# CY8C5868AXI_LP035 register map
File version: 0.1
Registers are 8-bit, read-write, no defined reset value unless marked. A register's access mark holds for its fields unless they carry their own. Offsets are from the block's base; [hi:lo] are bit positions; {n}, {i} and the like mark numbered series; 'fields as' and 'values as' point back to an identical list.

## LFSR
Base 0x40006406
0x00 SINGLE_CYCLE_SEED 14-bit — Current seed value
0x20 SINGLE_CYCLE_POLYNOMIAL 14-bit — Current polynomial value
0x40 SINGLE_CYCLE_COPY 14-bit — Copy seed value

## Length_Counter_1
Base 0x00000000
0x40006402 Length_Counter_1_COUNTER — UDB.A0 - Current Counter Value
0x40006422 Length_Counter_1_PERIOD — UDB.D0 - Assigned Period
0x40006432 Length_Counter_1_COMPARE — UDB.D1 - Assigned Compare Value
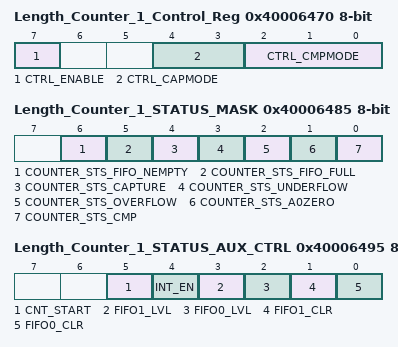
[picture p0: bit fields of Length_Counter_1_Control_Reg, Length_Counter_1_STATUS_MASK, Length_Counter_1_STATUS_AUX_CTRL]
0x40006470 Length_Counter_1_Control_Reg — UDB Control Register - Assigned Control Register Value
  [7] CTRL_ENABLE — Enable Counter
  [4:3] CTRL_CAPMODE — Capture mode
  [2:0] CTRL_CMPMODE — Compare mode
0x40006485 Length_Counter_1_STATUS_MASK — UDB Status bits Interrupt Mask Enable Register
  [6] COUNTER_STS_FIFO_NEMPTY — FIFO Not Empty Status
  [5] COUNTER_STS_FIFO_FULL — FIFO Full Status
  [4] COUNTER_STS_CAPTURE — Capture Status
  [3] COUNTER_STS_UNDERFLOW — Underflow status
  [2] COUNTER_STS_OVERFLOW — Overflow status
  [1] COUNTER_STS_A0ZERO — A0 Zero ouput status
  [0] COUNTER_STS_CMP — Compare output status
0x40006495 Length_Counter_1_STATUS_AUX_CTRL — UDB Auxilliary Control Register
  [5] CNT_START — FIFO0 clear
    0=E_CNT_START0 (Disable counter); 1=E_CNT_START1 (Enable counter)
  [4] INT_EN
    0=E_INT_EN0 (Interrupt disabled); 1=E_INT_EN1 (Interrupt enabled)
  [3] FIFO1_LVL — FIFO level
    0=E_FIFO_LVL_0 (FIFO LVL: input mode: FIFO not full; output mode: FIFO not empty); 1=E_FIFO_LVL_1 (FIFO LVL: input mode: FIFO at least 1/2 empty; output mode: FIFO at least 1/2 full)
  [2] FIFO0_LVL — FIFO level
    values as FIFO1_LVL
  [1] FIFO1_CLR — FIFO1 clear
    0=E_FIFO_CLR_0 (Normal FIFO operation); 1=E_FIFO_CLR_1 (Clear FIFO state)
  [0] FIFO0_CLR — FIFO0 clear
    values as FIFO1_CLR

## Counter_1
Base 0x00000000
0x400043A3 Counter_1_GLOBAL_ENABLE — PM.ACT.CFG
  [3:0] en_timer — Enable timer/counters.
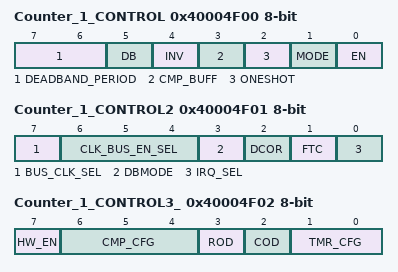
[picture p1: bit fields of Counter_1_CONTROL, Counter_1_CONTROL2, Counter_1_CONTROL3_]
0x40004F00 Counter_1_CONTROL — TMRx.CFG0
  [7:6] DEADBAND_PERIOD
  [5] DB — Deadband mode--Deadband phases phi1 and phi2 are outputted on CMP and TC output pins respectively.
    0=Timer (CMP and TC are output.); 1=Deadband (PHI1 (instead of CMP) and PHI2 (instead of TC) are output.)
  [4] INV — Invert sense of TIMEREN signal
  [3] CMP_BUFF — Buffer compare register. Compare register updates only on timer terminal count.
  [2] ONESHOT — Timer stops upon reaching stop condition defined by TMR_CFG bits. Can be restarted by asserting TIMER RESET or disabling and re-enabling block.
  [1] MODE — Mode. (0 = Timer; 1 = Comparator)
    0=Timer mode. CNT/CMP register holds timer count value.; 1=Comparator mode. CNT/CMP register holds comparator threshold value.
  [0] EN — Enables timer/comparator.
0x40004F01 Counter_1_CONTROL2 — TMRx.CFG1
  [7] BUS_CLK_SEL — Bus Clock selection.
  [6:4] CLK_BUS_EN_SEL — Digital Global Clock selection.
  [3] DBMODE — Deadband mode (asynchronous/synchronous). CMP output pin is also affected when not in deadband mode (CFG0.DEADBAND).
  [2] DCOR — Disable Clear on Read (DCOR) of Status Register SR0.
  [1] FTC — First Terminal Count (FTC). Setting this bit forces a single pulse on the TC pin when first enabled.
    0=Disable_FTC (Disable the single cycle pulse, which signifies the timer is starting.); 1=Enable_FTC (Enable the single cycle pulse, which signifies the timer is starting.)
  [0] IRQ_SEL — Irq selection. (0 = raw interrupts; 1 = status register interrupts)
0x40004F02 Counter_1_CONTROL3_ — TMRx.CFG2
  [7] HW_EN — When set Timer Enable controls counting.
  [6:4] CMP_CFG — Comparator configurations
    0=Equal (Compare Equal); 1=Less_than (Compare Less Than); 2=Less_than_or_equal (Compare Less Than or Equal .); 3=Greater (Compare Greater Than .); 4=Greater_than_or_equal (Compare Greater Than or Equal)
  [3] ROD — Reset On Disable (ROD). Resets internal state of output logic
  [2] COD — Clear On Disable (COD). Clears or gates outputs to zero.
  [1:0] TMR_CFG — Timer configuration (MODE = 0): 000 = Continuous; 001 = Pulsewidth; 010 = Period; 011 = Stop on IRQ
    0=Continuous (Timer runs while EN bit of CFG0 register is set to '1'.); 1=Pulsewidth (Timer runs from positive to negative edge of TIMEREN.); 2=Period (Timer runs from positive to positive edge of TIMEREN.); 3=Irq (Timer runs until IRQ.)
0x40004F04 Counter_1_PERIOD 16-bit — TMRx.PER0 - Assigned Period
0x40004F06 Counter_1_COUNTER 16-bit — TMRx.CNT_CMP0 - Current Down Counter Value

## VDAC8_Noise
Base 0x00000000
0x400043A8 VDAC8_PM_ACT_CFG — Active Power Mode Configuration Register 8
  [4:0] en_dac — Enable DAC block(s). Populated subsystems are counted from the LSB
0x400043B8 VDAC8_PM_STBY_CFG — Standby Power Mode Configuration Register 8
  fields as VDAC8_PM_ACT_CFG
0x4000460A VDAC8_TR
  [7:0] tr — 8 Calibration bits
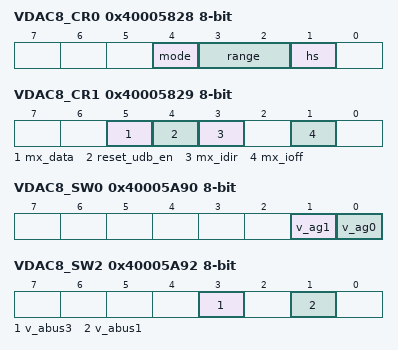
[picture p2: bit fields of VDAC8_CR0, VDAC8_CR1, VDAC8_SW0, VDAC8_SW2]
0x40005828 VDAC8_CR0 — DAC Block Control Register 0
  [4] mode ro — Mode Bit
    0=DAC_MODE_V (voltage DAC); 1=DAC_MODE_I (current DAC)
  [3:2] range — Ranges for mode=0 (VDAC) and mode=1 (IDAC)
    0=DAC_RANGE_0 (x0=0V to 4*vref (1.024V); 0 to 31.875uA); 1=DAC_RANGE_1 (x1=0V to 16*vref (4.096V); 0 to 255uA); 2=DAC_RANGE_2 (x0=0V to 4*vref (1.024V); 0 to 2.040mA); 3=DAC_RANGE_3 (x1=0V to 16*vref (4.096V); not used)
  [1] hs — High Speed Bit
    0=DAC_HS_LOWPOWER (regular (low power)); 1=DAC_HS_HIGHSPEED (high speed (higher power))
0x40005829 VDAC8_CR1 — DAC Block Control Register 1
  [5] mx_data — Select DATA source
    0=MX_DATA_REG (Select register source (DACxn_D)); 1=MX_DATA_UDB (Select UDB source)
  [4] reset_udb_en — DAC reset enable
    0=RESET_UDB_EN_DISABLE (Disable DAC Reset Source from UDB (System reset always resets)); 1=RESET_UDB_EN_ENABLE (Enable DAC Reset Source from UDB)
  [3] mx_idir — Mux selection for DAC current direction control
    0=MX_IDIR_REG (Register source idirbit selected); 1=MX_IDIR_UDB (UDB ictrl selected)
  [1] mx_ioff — Mux selection for DAC current off control
    0=MX_IOFF_REG (Register source ioffbit selected); 1=MX_IOFF_UDB (UDB ictrl selected)
0x40005A90 VDAC8_SW0 — DAC Analog Routing Register 0
  [1] v_ag1 — Connect voltage output to analog global of same side
    0=AG_NC (not connected); 1=AG_CONNECTED (Connect to Analog Global)
  [0] v_ag0 — Connect voltage output to analog global of same side
    values as v_ag1
0x40005A92 VDAC8_SW2 — DAC Analog Routing Register 2
  [3] v_abus3 — Connect voltage output to analog (local) bus of the same side
    0=ABUS_NC (not connected); 1=ABUS_CONNECTED (Connect to Analog (local) Bus)
  [1] v_abus1 — Connect voltage output to analog (local) bus of the same side
    values as v_abus3
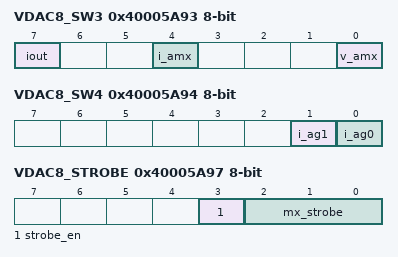
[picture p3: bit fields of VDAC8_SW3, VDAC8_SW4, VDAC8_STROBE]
0x40005A93 VDAC8_SW3 — DAC Analog Routing Register 3
  [7] iout — Connect current output to pad
    0=IOUT_NC (not connected); 1=IOUT_CONNECT (Connect to pad)
  [4] i_amx — Connect current output to Analog Mux Bus
    0=AMX_NC (not connected); 1=AMX_CONNECTED (Connect to AMUXBUS)
  [0] v_amx — Connect voltage output to Analog Mux Bus
    values as i_amx
0x40005A94 VDAC8_SW4 — DAC Analog Routing Register 4
  [1] i_ag1 — Connect current output to analog global of same side
    values as VDAC8_SW0.v_ag1
  [0] i_ag0 — Connect current output to analog global of same side
    values as VDAC8_SW0.v_ag1
0x40005A97 VDAC8_STROBE — DAC Strobe Register
  [3] strobe_en — Strobe gating control (See mx_strobe==3'h0)
    0=disable strobe; 1=enable strobe
  [2:0] mx_strobe — Strobe source selection
    0=MX_STROBE_BUSWRITE (Select bus write strobe source (Enable gater regardless of strobe_en setting)); 1=MX_STROBE_UDB_SRC (Select UDB strobe source); 2=MX_STROBE_NC_2 (NC); 3=MX_STROBE_NC_3 (NC); {v}=MX_STROBE_CLK_A{v-4}_DIG (Select clk_a{v-4}_dig) (v=4..7)
0x40005B82 VDAC8_DATA — DAC Data Register
  [7:0] data — 8 DAC Data bits
